# STM32U575xx register map
File version: 1.0
Registers are 32-bit, read-write, reset 0x0 unless marked. A register's access mark holds for its fields unless they carry their own. Offsets are from the block's base; [hi:lo] are bit positions; {n}, {i} and the like mark numbered series.

## PSSI
Base 0x4202C400
Same registers: PSSI_S 0x5202C400
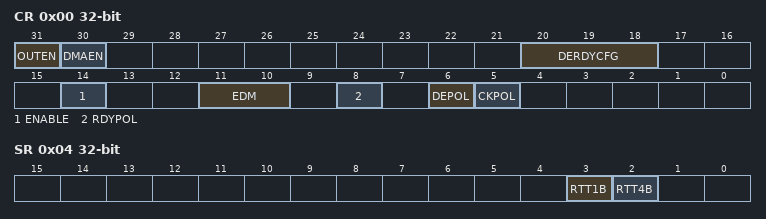
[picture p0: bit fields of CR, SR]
0x00 CR — PSSI control register
  [31] OUTEN — Data direction selection
  [30] DMAEN — DMA enable
  [20:18] DERDYCFG — Data enable and ready configuration
  [14] ENABLE — PSSI enable
  [11:10] EDM — Extended data mode
  [8] RDYPOL — Ready polarity
  [6] DEPOL — Data enable polarity
  [5] CKPOL — Parallel data clock polarity
0x04 SR — PSSI status register
  [3] RTT1B — Ready to transfer one byte
  [2] RTT4B — Ready to transfer four bytes
0x08 RIS — PSSI raw interrupt status register
  [1] OVR_RIS — Data buffer overrun/underrun raw interrupt status
0x0C IER — PSSI interrupt enable register
  [1] OVR_IE — Data buffer overrun/underrun interrupt enable
0x10 MIS — PSSI masked interrupt status register
  [1] OVR_MIS — Data buffer overrun/underrun masked interrupt status
0x14 ICR — PSSI interrupt clear register
  [1] OVR_ISC — Data buffer overrun/underrun interrupt status clear
0x28 DR — PSSI data register
  [31:0] DR — Data register

## HASH
Base 0x420C0400
Same registers: HASH_S 0x520C0400
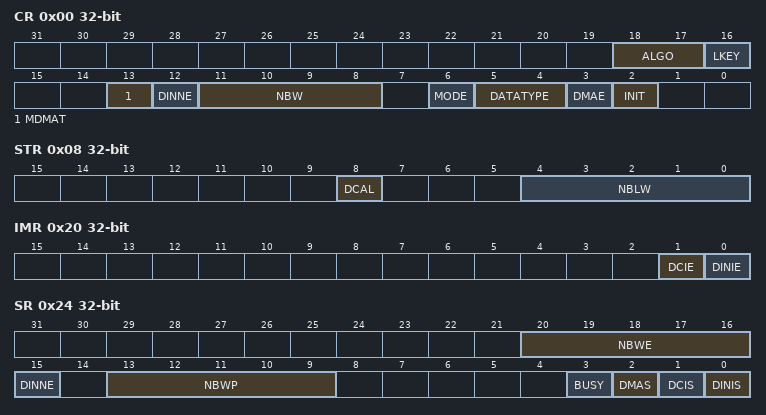
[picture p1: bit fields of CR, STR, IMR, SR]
0x00 CR — HASH control register
  [18:17] ALGO, [16] LKEY, [13] MDMAT, [12] DINNE, [11:8] NBW, [6] MODE, [5:4] DATATYPE, [3] DMAE, [2] INIT
0x04 DIN — HASH data input register
0x08 STR — HASH start register
  [8] DCAL, [4:0] NBLW
{0xC+4i} HR{i} (i=0..4) — HASH digest registers
0x20 IMR — HASH interrupt enable register
  [1] DCIE, [0] DINIE
0x24 SR — HASH status register
  [20:16] NBWE, [15] DINNE, [13:9] NBWP, [3] BUSY, [2] DMAS, [1] DCIS, [0] DINIS
{0xF8+4i} CSR{i} (i=0..53) — HASH context swap registers
{0x310+4i} DIGEST_HR{i} (i=0..7) — HASH digest registers

## RNG
Base 0x420C0800
Same registers: RNG_S 0x520C0800
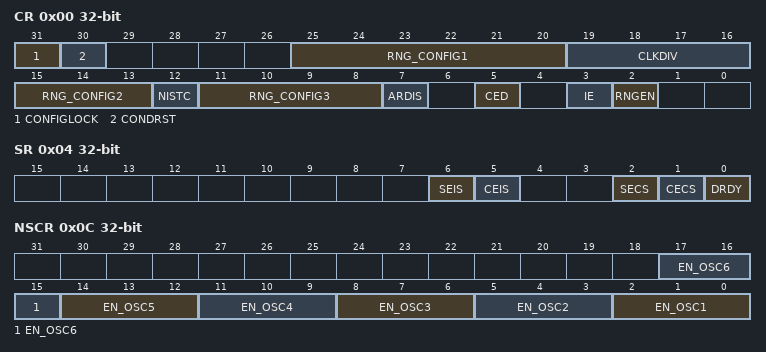
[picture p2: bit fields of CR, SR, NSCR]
0x00 CR — RNG control register
  [31] CONFIGLOCK
  [30] CONDRST
  [25:20] RNG_CONFIG1
  [19:16] CLKDIV
    0=BY_1 (No clock division); 1=BY_2 (2 RNG clock cycles per internal RNG clock); 2=BY_4 (4 RNG clock cycles per internal RNG clock); 3=BY_8 (8 RNG clock cycles per internal RNG clock); 4=BY_16 (16 RNG clock cycles per internal RNG clock); 5=BY_32 (32 RNG clock cycles per internal RNG clock); 6=BY_64 (64 RNG clock cycles per internal RNG clock); 7=BY_128 (128 RNG clock cycles per internal RNG clock); 8=BY_256 (256 RNG clock cycles per internal RNG clock); 9=BY_512 (512 RNG clock cycles per internal RNG clock); 10=BY_1024 (1024 RNG clock cycles per internal RNG clock); 11=BY_2048 (2048 RNG clock cycles per internal RNG clock); 12=BY_4096 (4096 RNG clock cycles per internal RNG clock); 13=BY_8192 (8192 RNG clock cycles per internal RNG clock); 14=BY_16384 (16384 RNG clock cycles per internal RNG clock); 15=BY_32768 (32768 RNG clock cycles per internal RNG clock)
  [15:13] RNG_CONFIG2
  [12] NISTC
  [11:8] RNG_CONFIG3
  [7] ARDIS
  [5] CED
  [3] IE
  [2] RNGEN
0x04 SR — RNG status register
  [6] SEIS, [5] CEIS, [2] SECS, [1] CECS, [0] DRDY
0x08 DR — RNG data register
0x0C NSCR — RNG noise source control register
  [3n-1:3n-3] EN_OSC{n} (n=1..6)
0x10 HTCR — RNG health test configuration register
  [31:0] HTCFG

## OCTOSPIM — Serial Peripheral Interface IO Manager
Base 0x420C4000
Same registers: OCTOSPIM_S 0x520C4000
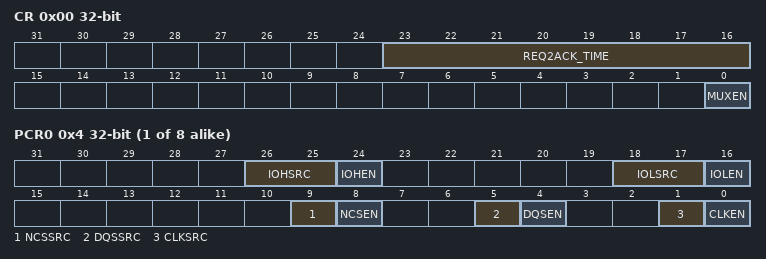
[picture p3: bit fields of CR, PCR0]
0x00 CR — OCTOSPIM IO Manager Control register
  [23:16] REQ2ACK_TIME — REQ to ACK Time
  [0] MUXEN — Multiplexed Mode Enable
{0x4+4i} PCR{i} (i=0..7) — OCTOSPIM IO Manager Port[1:8] Configuration register
  [26:25] IOHSRC — IO[7:4] Source for Port n
  [24] IOHEN — IO[7:4] Enable for Port n
  [18:17] IOLSRC — IO[3:0] Source for Port n
  [16] IOLEN — IO[3:0] Enable for Port n
  [9] NCSSRC — nCS Source for Port n
  [8] NCSEN — nCS Enable for Port n
  [5] DQSSRC — DQS Source for Port n
  [4] DQSEN — DQS Enable for Port n
  [1] CLKSRC — CLK/CLKn Source for Port n
  [0] CLKEN — CLK/CLKn Enable for Port n
